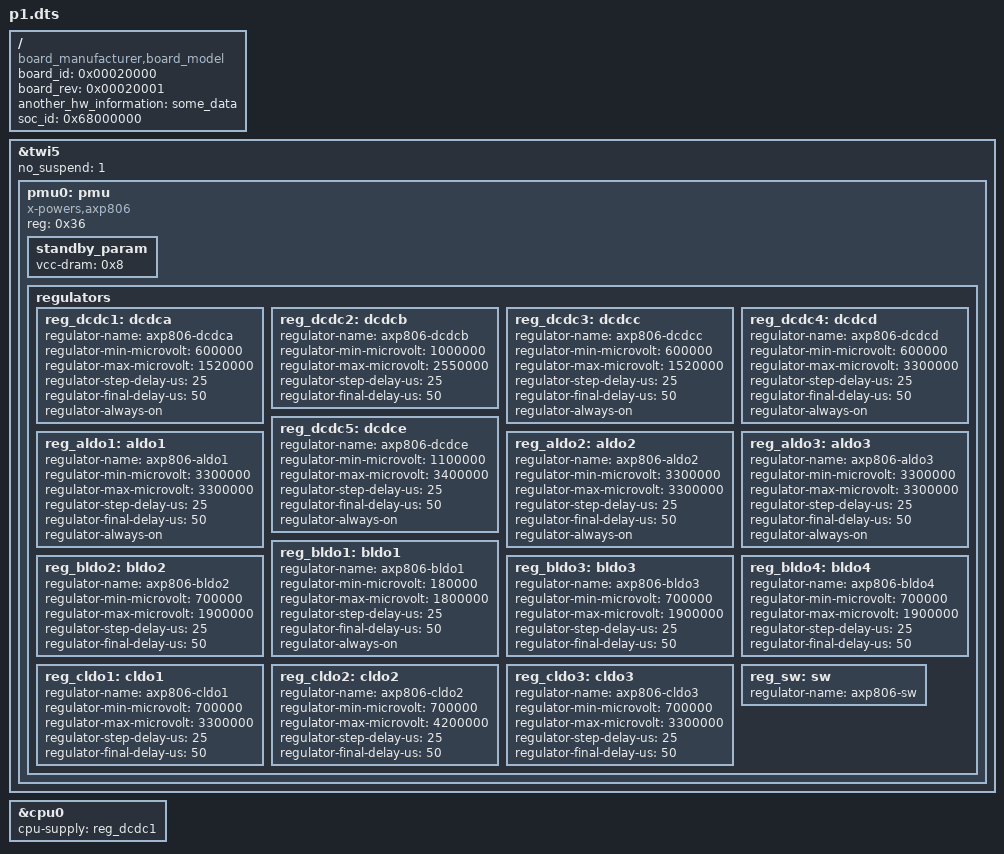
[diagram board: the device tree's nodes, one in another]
/dts-v1/;
/plugin/;
/ {
  /* As DTS design, these properties only for loader, won't overlay */
  compatible = "board_manufacturer,board_model";

  /* These properties are examples */
  board_id = <0x00020000>;
  board_rev = <0x00020001>;
  another_hw_information = "some_data";
  soc_id = <0x68000000>;

	fragment@1 {
		target = <&twi5>;
		__overlay__ {
			#address-cells = <1>;
			#size-cells = <0>;
			no_suspend = <1>;
			status = "okay";

			pmu0: pmu{
				compatible = "x-powers,axp806";
				reg = <0x36>;

				standby_param: standby_param {
					vcc-dram = <0x8>;
				};

				regulators{
					reg_dcdc1: dcdca {
						regulator-name = "axp806-dcdca";
						regulator-min-microvolt = <600000>;
						regulator-max-microvolt = <1520000>;
						regulator-step-delay-us = <25>;
						regulator-final-delay-us = <50>;
						regulator-always-on;
					};

					reg_dcdc2: dcdcb {
						regulator-name = "axp806-dcdcb";
						regulator-min-microvolt = <1000000>;
						regulator-max-microvolt = <2550000>;
						regulator-step-delay-us = <25>;
						regulator-final-delay-us = <50>;
					};

					reg_dcdc3: dcdcc {
						regulator-name = "axp806-dcdcc";
						regulator-min-microvolt = <600000>;
						regulator-max-microvolt = <1520000>;
						regulator-step-delay-us = <25>;
						regulator-final-delay-us = <50>;
						regulator-always-on;
					};

					reg_dcdc4: dcdcd {
						regulator-name = "axp806-dcdcd";
						regulator-min-microvolt = <600000>;
						regulator-max-microvolt = <3300000>;
						regulator-step-delay-us = <25>;
						regulator-final-delay-us = <50>;
						regulator-always-on;
					};

					reg_dcdc5: dcdce {
						regulator-name = "axp806-dcdce";
						regulator-min-microvolt = <1100000>;
						regulator-max-microvolt = <3400000>;
						regulator-step-delay-us = <25>;
						regulator-final-delay-us = <50>;
						regulator-always-on;
					};

					reg_aldo1: aldo1 {
						regulator-name = "axp806-aldo1";
						regulator-min-microvolt = <3300000>;
						regulator-max-microvolt = <3300000>;
						regulator-step-delay-us = <25>;
						regulator-final-delay-us = <50>;
						regulator-always-on;
					};
					reg_aldo2: aldo2 {
						regulator-name = "axp806-aldo2";
						regulator-min-microvolt = <3300000>;
						regulator-max-microvolt = <3300000>;
						regulator-step-delay-us = <25>;
						regulator-final-delay-us = <50>;
						regulator-always-on;
					};
					reg_aldo3: aldo3 {
						regulator-name = "axp806-aldo3";
						regulator-min-microvolt = <3300000>;
						regulator-max-microvolt = <3300000>;
						regulator-step-delay-us = <25>;
						regulator-final-delay-us = <50>;
						regulator-always-on;
					};
					reg_bldo1: bldo1 {
						regulator-name = "axp806-bldo1";
						regulator-min-microvolt = <180000>;
						regulator-max-microvolt = <1800000>;
						regulator-step-delay-us = <25>;
						regulator-final-delay-us = <50>;
						regulator-always-on;
					};
					reg_bldo2: bldo2 {
						regulator-name = "axp806-bldo2";
						regulator-min-microvolt = <700000>;
						regulator-max-microvolt = <1900000>;
						regulator-step-delay-us = <25>;
						regulator-final-delay-us = <50>;
					};
					reg_bldo3: bldo3 {
						regulator-name = "axp806-bldo3";
						regulator-min-microvolt = <700000>;
						regulator-max-microvolt = <1900000>;
						regulator-step-delay-us = <25>;
						regulator-final-delay-us = <50>;
					};
					reg_bldo4: bldo4 {
						regulator-name = "axp806-bldo4";
						regulator-min-microvolt = <700000>;
						regulator-max-microvolt = <1900000>;
						regulator-step-delay-us = <25>;
						regulator-final-delay-us = <50>;
					};
					reg_cldo1: cldo1 {
						regulator-name = "axp806-cldo1";
						regulator-min-microvolt = <700000>;
						regulator-max-microvolt = <3300000>;
						regulator-step-delay-us = <25>;
						regulator-final-delay-us = <50>;
					};
					reg_cldo2: cldo2 {
						regulator-name = "axp806-cldo2";
						regulator-min-microvolt = <700000>;
						regulator-max-microvolt = <4200000>;
						regulator-step-delay-us = <25>;
						regulator-final-delay-us = <50>;
					};
					reg_cldo3: cldo3 {
						regulator-name = "axp806-cldo3";
						regulator-min-microvolt = <700000>;
						regulator-max-microvolt = <3300000>;
						regulator-step-delay-us = <25>;
						regulator-final-delay-us = <50>;
					};
					reg_sw: sw {
						regulator-name = "axp806-sw";
					};
				};
			};
		};
	};
	fragment@2 {
		target = <&cpu0>;
		__overlay__{
			cpu-supply = <&reg_dcdc1>;
		};
	};
};
